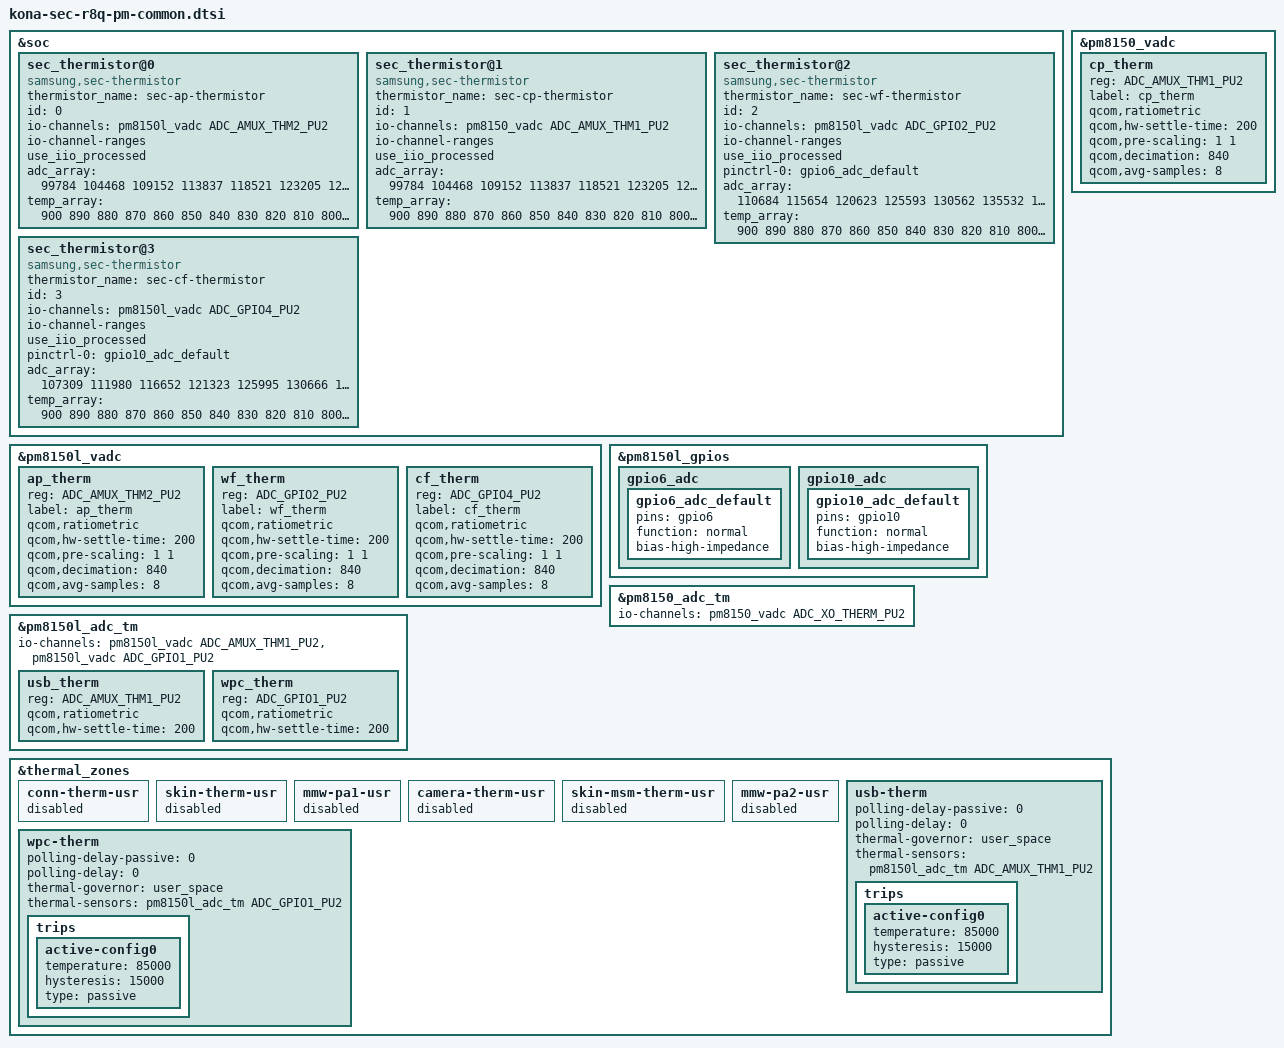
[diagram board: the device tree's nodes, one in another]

/* Copyright (c) 2014, The Linux Foundation. All rights reserved.
 *
 * This program is free software; you can redistribute it and/or modify
 * it under the terms of the GNU General Public License version 2 and
 * only version 2 as published by the Free Software Foundation.
 *
 * This program is distributed in the hope that it will be useful,
 * but WITHOUT ANY WARRANTY; without even the implied warranty of
 * MERCHANTABILITY or FITNESS FOR A PARTICULAR PURPOSE.  See the
 * GNU General Public License for more details.
 */

#include <dt-bindings/regulator/qcom,rpmh-regulator-levels.h>

&soc {
	/* AP Thermistor table */
	sec_thermistor@0 {
		compatible = "samsung,sec-thermistor";
		status = "okay";
		thermistor_name = "sec-ap-thermistor";
		id = <0>;

		io-channels = <&pm8150l_vadc ADC_AMUX_THM2_PU2>;
		io-channel-names = "ap_therm";
		io-channel-ranges;
		use_iio_processed;

		adc_array = <99784 104468 109152 113837 118521 123205 127889 132573 137258 141942
				146626 152296 157967 163637 169308 174978 181258 187538 193819 200099
				206379 214671 222962 231254 239545 247837 255648 263460 271271 279083
				286894 299480 312067 324653 337240 349826 361452 373079 384705 396332
				407958 423023 438088 453152 468217 483282 500228 517175 534121 551068
				568014 592331 616647 640964 665280 689597 702780 715964 729147 742331
				755514 775743 795972 816202 836431 856660 880964 905268 929571 953875
				978179 1000523 1022867 1045212 1067556 1089900 1111038 1132175 1153313 1174450
				1195588 1215142 1234697 1254251 1273806 1293360 1312434 1331509 1350583 1369658
				1388732
				1407197 1425661 1444126 1462590 1481055 1498053 1515051 1532050 1549048 1566046
				1579074 1592102 1605129 1618157 1631185 1642033 1652880 1663728 1674575 1685423>;

		temp_array = <900 890 880 870 860 850 840 830 820 810
				800 790 780 770 760 750 740 730 720 710
				700 690 680 670 660 650 640 630 620 610
				600 590 580 570 560 550 540 530 520 510
				500 490 480 470 460 450 440 430 420 410
				400 390 380 370 360 350 340 330 320 310
				300 290 280 270 260 250 240 230 220 210
				200 190 180 170 160 150 140 130 120 110
				100 90 80 70 60 50 40 30 20 10
				0
				(-10) (-20) (-30) (-40) (-50) (-60) (-70) (-80) (-90) (-100)
				(-110)(-120)(-130)(-140)(-150)(-160)(-170)(-180)(-190) (-200)>;
	};

	/* CP Thermistor table */
	sec_thermistor@1 {
		compatible = "samsung,sec-thermistor";
		status = "okay";
		thermistor_name = "sec-cp-thermistor";
		id = <1>;

		io-channels = <&pm8150_vadc ADC_AMUX_THM1_PU2>;
		io-channel-names = "cp_therm";
		io-channel-ranges;
		use_iio_processed;

		adc_array = <99784 104468 109152 113837 118521 123205 127889 132573 137258 141942
				146626 152296 157967 163637 169308 174978 181258 187538 193819 200099
				206379 214671 222962 231254 239545 247837 255648 263460 271271 279083
				286894 299480 312067 324653 337240 349826 361452 373079 384705 396332
				407958 423023 438088 453152 468217 483282 500228 517175 534121 551068
				568014 592331 616647 640964 665280 689597 702780 715964 729147 742331
				755514 775743 795972 816202 836431 856660 880964 905268 929571 953875
				978179 1000523 1022867 1045212 1067556 1089900 1111038 1132175 1153313 1174450
				1195588 1215142 1234697 1254251 1273806 1293360 1312434 1331509 1350583 1369658
				1388732
				1407197 1425661 1444126 1462590 1481055 1498053 1515051 1532050 1549048 1566046
				1579074 1592102 1605129 1618157 1631185 1642033 1652880 1663728 1674575 1685423>;

		temp_array = <900 890 880 870 860 850 840 830 820 810
				800 790 780 770 760 750 740 730 720 710
				700 690 680 670 660 650 640 630 620 610
				600 590 580 570 560 550 540 530 520 510
				500 490 480 470 460 450 440 430 420 410
				400 390 380 370 360 350 340 330 320 310
				300 290 280 270 260 250 240 230 220 210
				200 190 180 170 160 150 140 130 120 110
				100 90 80 70 60 50 40 30 20 10
				0
				(-10) (-20) (-30) (-40) (-50) (-60) (-70) (-80) (-90) (-100)
				(-110)(-120)(-130)(-140)(-150)(-160)(-170)(-180)(-190) (-200)>;
	};

	/* WiFi Thermistor table */
	sec_thermistor@2 {
		compatible = "samsung,sec-thermistor";
		status = "okay";
		thermistor_name = "sec-wf-thermistor";
		id = <2>;

		io-channels = <&pm8150l_vadc ADC_GPIO2_PU2>;
		io-channel-names = "wf_therm";
		io-channel-ranges;
		use_iio_processed;

		pinctrl-names = "default";
		pinctrl-0 = <&gpio6_adc_default>;

		adc_array = <110684 115654 120623 125593 130562 135532 140502 145471 150441 155410
				160380 166466 172551 178637 184722 190808 198023 205237 212452 219666
				226881 235043 243205 251366 259528 267690 276306 284922 293537 302153
				310769 322875 334982 347088 359195 371301 383939 396578 409216 421855
				434493 450246 465998 481751 497503 513256 529826 546396 562967 579537
				596107 621215 646323 671431 696539 721647 736478 751310 766141 780973
				795804 816007 836210 856414 876617 896820 919748 942676 965605 988533
				1011461 1033715 1055968 1078222 1100475 1122729 1143879 1165030 1186180 1207331
				1228481 1248775 1269069 1289364 1309658 1329952 1348871 1367789 1386708 1405626
				1424545
				1441920 1459294 1476669 1494043 1511418 1526405 1541392 1556379 1571366 1586353
				1599329 1612305 1625280 1638256 1651232 1661535 1671838 1682140 1692443 1702746>;

		temp_array = <900 890 880 870 860 850 840 830 820 810
				800 790 780 770 760 750 740 730 720 710
				700 690 680 670 660 650 640 630 620 610
				600 590 580 570 560 550 540 530 520 510
				500 490 480 470 460 450 440 430 420 410
				400 390 380 370 360 350 340 330 320 310
				300 290 280 270 260 250 240 230 220 210
				200 190 180 170 160 150 140 130 120 110
				100 90 80 70 60 50 40 30 20 10
				0
				(-10) (-20) (-30) (-40) (-50) (-60) (-70) (-80) (-90) (-100)
				(-110)(-120)(-130)(-140)(-150)(-160)(-170)(-180)(-190) (-200)>;
	};

	/* Camera Flash Thermistor table */
	sec_thermistor@3 {
		compatible = "samsung,sec-thermistor";
		status = "okay";
		thermistor_name = "sec-cf-thermistor";
		id = <3>;

		io-channels = <&pm8150l_vadc ADC_GPIO4_PU2>;
		io-channel-names = "cf_therm";
		io-channel-ranges;
		use_iio_processed;

		pinctrl-names = "default";
		pinctrl-0 = <&gpio10_adc_default>;

		adc_array = <107309 111980 116652 121323 125995 130666 136453 142240 148028 153815
				159602 166583 173564 180544 187525 194506 201811 209117 216422 223728
				231033 240324 249615 258905 268196 277487 287556 297625 307695 317764
				327833 339836 351838 363841 375843 387846 401847 415848 429848 443849
				457850 473447 489044 504640 520237 535834 554208 572582 590955 609329
				627703 646258 664814 683369 701925 720480 740839 761198 781557 801916
				822275 844645 867015 889386 911756 934126 949982 965839 981695 997552
				1013408 1036816 1060224 1083633 1107041 1130449 1151755 1173061 1194368 1215674
				1236980 1256353 1275726 1295099 1314472 1333845 1348378 1362911 1377443 1391976
				1406509
				1425700 1444891 1464083 1483274 1502465 1516388 1530311 1544234 1558157 1572080
				1585640 1599199 1612759 1626318 1639878 1650635 1661392 1672149 1682906 1693663>;

		temp_array = <900 890 880 870 860 850 840 830 820 810
				800 790 780 770 760 750 740 730 720 710
				700 690 680 670 660 650 640 630 620 610
				600 590 580 570 560 550 540 530 520 510
				500 490 480 470 460 450 440 430 420 410
				400 390 380 370 360 350 340 330 320 310
				300 290 280 270 260 250 240 230 220 210
				200 190 180 170 160 150 140 130 120 110
				100 90 80 70 60 50 40 30 20 10
				0
				(-10) (-20) (-30) (-40) (-50) (-60) (-70) (-80) (-90) (-100)
				(-110)(-120)(-130)(-140)(-150)(-160)(-170)(-180)(-190) (-200)>;
	};
};

&pm8150_vadc {
	/delete-node/ skin_therm;
	cp_therm {
		reg = <ADC_AMUX_THM1_PU2>;
		label = "cp_therm";
		qcom,ratiometric;
		qcom,hw-settle-time = <200>;
		qcom,pre-scaling = <1 1>;
		qcom,decimation = <840>;
		qcom,avg-samples = <8>;
	};
};

&pm8150l_vadc {
	/delete-node/ skin_msm_therm;
	ap_therm {
		reg = <ADC_AMUX_THM2_PU2>;
		label = "ap_therm";
		qcom,ratiometric;
		qcom,hw-settle-time = <200>;
		qcom,pre-scaling = <1 1>;
		qcom,decimation = <840>;
		qcom,avg-samples = <8>;
	};

	wf_therm {
		reg = <ADC_GPIO2_PU2>;
		label = "wf_therm";
		qcom,ratiometric;
		qcom,hw-settle-time = <200>;
		qcom,pre-scaling = <1 1>;
		qcom,decimation = <840>;
		qcom,avg-samples = <8>;
	};

	cf_therm {
		reg = <ADC_GPIO4_PU2>;
		label = "cf_therm";
		qcom,ratiometric;
		qcom,hw-settle-time = <200>;
		qcom,pre-scaling = <1 1>;
		qcom,decimation = <840>;
		qcom,avg-samples = <8>;
	};
};

&pm8150l_gpios {
	gpio6_adc {
		gpio6_adc_default: gpio6_adc_default {
			pins = "gpio6";
			function = "normal";
			bias-high-impedance;
		};
	};

	gpio10_adc {
		gpio10_adc_default: gpio10_adc_default {
			pins = "gpio10";
			function = "normal";
			bias-high-impedance;
		};
	};
};

&pm8150_adc_tm {
	io-channels = <&pm8150_vadc ADC_XO_THERM_PU2>;
	/delete-node/ skin_therm@4d;
	/delete-node/ pa_therm1@4e;
};

&pm8150l_adc_tm {
	io-channels = <&pm8150l_vadc ADC_AMUX_THM1_PU2>,
			<&pm8150l_vadc ADC_GPIO1_PU2>;

	/delete-node/ camera_flash_therm@4d;
	/delete-node/ skin_msm_therm@4e;
	/delete-node/ pa_therm2@4f;

	usb_therm {
		reg = <ADC_AMUX_THM1_PU2>;
		qcom,ratiometric;
		qcom,hw-settle-time = <200>;
	};

	wpc_therm {
		reg = <ADC_GPIO1_PU2>;
		qcom,ratiometric;
		qcom,hw-settle-time = <200>;
	};
};

&thermal_zones {
	conn-therm-usr {
		status = "disabled"; 
	};
	skin-therm-usr {
		status = "disabled"; 
	};
	mmw-pa1-usr {
		status = "disabled"; 
	};
	camera-therm-usr {
		status = "disabled"; 
	};
	skin-msm-therm-usr {
		status = "disabled";
	};
	mmw-pa2-usr {
		status = "disabled"; 
	};

	usb-therm {
		polling-delay-passive = <0>;
		polling-delay = <0>;
		thermal-governor = "user_space";
		thermal-sensors = <&pm8150l_adc_tm ADC_AMUX_THM1_PU2>;
		trips {
			active-config0 {
				temperature = <85000>;
				hysteresis = <15000>;
				type = "passive";
			};
		};
	};

	wpc-therm {
		polling-delay-passive = <0>;
		polling-delay = <0>;
		thermal-governor = "user_space";
		thermal-sensors = <&pm8150l_adc_tm ADC_GPIO1_PU2>;
		trips {
			active-config0 {
				temperature = <85000>;
				hysteresis = <15000>;
				type = "passive";
			};
		};
	};
};
